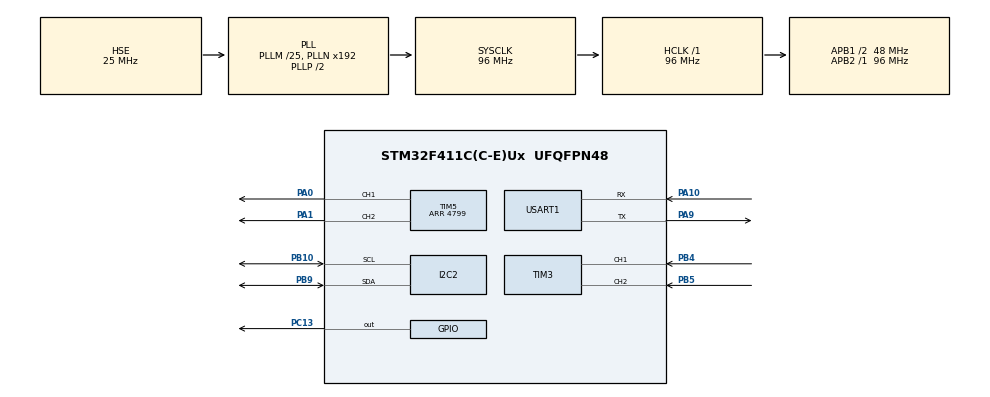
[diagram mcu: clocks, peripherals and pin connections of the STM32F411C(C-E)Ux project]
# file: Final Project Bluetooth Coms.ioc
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I2C2.I2C_Mode=I2C_Fast
Mcu.Family=STM32F4
Mcu.Name=STM32F411C(C-E)Ux
Mcu.Package=UFQFPN48
NVIC.I2C2_ER_IRQn=true\:0\:0\:false\:false\:true\:true\:true\:true
NVIC.I2C2_EV_IRQn=true\:0\:0\:false\:false\:true\:true\:true\:true
NVIC.PriorityGroup=NVIC_PRIORITYGROUP_4
NVIC.TIM3_IRQn=true\:0\:0\:false\:false\:true\:true\:true\:true
NVIC.USART1_IRQn=true\:0\:0\:false\:false\:true\:true\:true\:true
PA0-WKUP.Signal=S_TIM5_CH1
PA1.Signal=S_TIM5_CH2
PA10.Mode=Asynchronous
PA10.Signal=USART1_RX
PA13.Mode=Serial_Wire
PA13.Signal=SYS_JTMS-SWDIO
PA14.Mode=Serial_Wire
PA14.Signal=SYS_JTCK-SWCLK
PA9.Mode=Asynchronous
PA9.Signal=USART1_TX
PB10.GPIO_Pu=GPIO_NOPULL
PB10.Mode=I2C
PB10.Signal=I2C2_SCL
PB4.GPIO_ModeDefaultPP=GPIO_MODE_AF_OD
PB4.GPIO_PuPd=GPIO_PULLUP
PB4.Signal=S_TIM3_CH1
PB5.GPIO_ModeDefaultPP=GPIO_MODE_AF_OD
PB5.GPIO_PuPd=GPIO_PULLUP
PB5.Signal=S_TIM3_CH2
PB9.GPIO_Pu=GPIO_NOPULL
PB9.Mode=I2C
PB9.Signal=I2C2_SDA
PC13-ANTI_TAMP.Signal=GPIO_Output
PH0\ -\ OSC_IN.Mode=HSE-External-Oscillator
PH0\ -\ OSC_IN.Signal=RCC_OSC_IN
PH1\ -\ OSC_OUT.Mode=HSE-External-Oscillator
PH1\ -\ OSC_OUT.Signal=RCC_OSC_OUT
ProjectManager.HeapSize=0x200
ProjectManager.StackSize=0x400
ProjectManager.TargetToolchain=STM32CubeIDE
RCC.48MHZClocksFreq_Value=48000000
RCC.AHBFreq_Value=96000000
RCC.APB1CLKDivider=RCC_HCLK_DIV2
RCC.APB1Freq_Value=48000000
RCC.APB1TimFreq_Value=96000000
RCC.APB2Freq_Value=96000000
RCC.APB2TimFreq_Value=96000000
RCC.CortexFreq_Value=96000000
RCC.HCLKFreq_Value=96000000
RCC.HSE_VALUE=25000000
RCC.HSI_VALUE=16000000
RCC.LSE_VALUE=32768
RCC.PLLM=25
RCC.PLLSourceVirtual=RCC_PLLSOURCE_HSE
RCC.SYSCLKFreq_VALUE=96000000
RCC.SYSCLKSource=RCC_SYSCLKSOURCE_PLLCLK
RCC.VCOOutputFreq_Value=192000000
SH.S_TIM3_CH1.0=TIM3_CH1,Encoder_Interface
SH.S_TIM3_CH2.0=TIM3_CH2,Encoder_Interface
SH.S_TIM5_CH1.0=TIM5_CH1,PWM Generation1 CH1
SH.S_TIM5_CH2.0=TIM5_CH2,PWM Generation2 CH2
TIM2.Period=4799
TIM2.Prescaler=0
TIM3.AutoReloadPreload=TIM_AUTORELOAD_PRELOAD_DISABLE
TIM5.Channel-PWM\ Generation1\ CH1=TIM_CHANNEL_1
TIM5.Channel-PWM\ Generation2\ CH2=TIM_CHANNEL_2
TIM5.OCPolarity_1=TIM_OCPOLARITY_LOW
TIM5.OCPolarity_2=TIM_OCPOLARITY_LOW
TIM5.Period=4799
USART1.VirtualMode=VM_ASYNC
VP_TIM1_VS_ClockSourceITR.Mode=TriggerSource_ITR0
VP_TIM2_VS_ClockSourceINT.Mode=Internal
board=custom

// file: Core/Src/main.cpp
/* USER CODE BEGIN Header */
/**
  ******************************************************************************
  * @file           : main.c
  * @brief          : Main program body
  ******************************************************************************
  * @attention
  *
  * Copyright (c) 2023 STMicroelectronics.
  * All rights reserved.
  *
  * This software is licensed under terms that can be found in the LICENSE file
  * in the root directory of this software component.
  * If no LICENSE file comes with this software, it is provided AS-IS.
  *
  ******************************************************************************
  */
/* USER CODE END Header */
#include "main.h"

/* USER CODE BEGIN Includes */
#include <stdio.h>
#include "coms.h"

/* USER CODE END Includes */

I2C_HandleTypeDef hi2c2;

TIM_HandleTypeDef htim1;
TIM_HandleTypeDef htim2;
TIM_HandleTypeDef htim3;
TIM_HandleTypeDef htim5;

UART_HandleTypeDef huart1;

/* USER CODE BEGIN PV */
UART_HandleTypeDef* coms::uart;
char	coms::messbuff[10];
/* USER CODE END PV */

void SystemClock_Config(void);
static void MX_GPIO_Init(void);
static void MX_TIM2_Init(void);
static void MX_USART1_UART_Init(void);
static void MX_TIM1_Init(void);
static void MX_I2C2_Init(void);
static void MX_TIM3_Init(void);
static void MX_TIM5_Init(void);

int main(void)
{

  /* MCU Configuration--------------------------------------------------------*/

  /* Reset of all peripherals, Initializes the Flash interface and the Systick. */
  HAL_Init();

  /* Configure the system clock */
  SystemClock_Config();

  /* Initialize all configured peripherals */
  MX_GPIO_Init();
  MX_TIM2_Init();
  MX_USART1_UART_Init();
  MX_TIM1_Init();
  MX_I2C2_Init();
  MX_TIM3_Init();
  MX_TIM5_Init();

  /* Infinite loop */
  while (1)
  {

  }
}

void SystemClock_Config(void)
{
  RCC_OscInitTypeDef RCC_OscInitStruct = {0};
  RCC_ClkInitTypeDef RCC_ClkInitStruct = {0};

  /** Configure the main internal regulator output voltage
  */
  __HAL_RCC_PWR_CLK_ENABLE();
  __HAL_PWR_VOLTAGESCALING_CONFIG(PWR_REGULATOR_VOLTAGE_SCALE1);

  /** Initializes the RCC Oscillators according to the specified parameters
  * in the RCC_OscInitTypeDef structure.
  */
  RCC_OscInitStruct.OscillatorType = RCC_OSCILLATORTYPE_HSE;
  RCC_OscInitStruct.HSEState = RCC_HSE_ON;
  RCC_OscInitStruct.PLL.PLLState = RCC_PLL_ON;
  RCC_OscInitStruct.PLL.PLLSource = RCC_PLLSOURCE_HSE;
  RCC_OscInitStruct.PLL.PLLM = 25;
  RCC_OscInitStruct.PLL.PLLN = 192;
  RCC_OscInitStruct.PLL.PLLP = RCC_PLLP_DIV2;
  RCC_OscInitStruct.PLL.PLLQ = 4;
  if (HAL_RCC_OscConfig(&RCC_OscInitStruct) != HAL_OK)
  {
    Error_Handler();
  }

  /** Initializes the CPU, AHB and APB buses clocks
  */
  RCC_ClkInitStruct.ClockType = RCC_CLOCKTYPE_HCLK|RCC_CLOCKTYPE_SYSCLK
                              |RCC_CLOCKTYPE_PCLK1|RCC_CLOCKTYPE_PCLK2;
  RCC_ClkInitStruct.SYSCLKSource = RCC_SYSCLKSOURCE_PLLCLK;
  RCC_ClkInitStruct.AHBCLKDivider = RCC_SYSCLK_DIV1;
  RCC_ClkInitStruct.APB1CLKDivider = RCC_HCLK_DIV2;
  RCC_ClkInitStruct.APB2CLKDivider = RCC_HCLK_DIV1;

  if (HAL_RCC_ClockConfig(&RCC_ClkInitStruct, FLASH_LATENCY_3) != HAL_OK)
  {
    Error_Handler();
  }
}

static void MX_I2C2_Init(void)
{

  hi2c2.Instance = I2C2;
  hi2c2.Init.ClockSpeed = 400000;
  hi2c2.Init.DutyCycle = I2C_DUTYCYCLE_2;
  hi2c2.Init.OwnAddress1 = 0;
  hi2c2.Init.AddressingMode = I2C_ADDRESSINGMODE_7BIT;
  hi2c2.Init.DualAddressMode = I2C_DUALADDRESS_DISABLE;
  hi2c2.Init.OwnAddress2 = 0;
  hi2c2.Init.GeneralCallMode = I2C_GENERALCALL_DISABLE;
  hi2c2.Init.NoStretchMode = I2C_NOSTRETCH_DISABLE;
  if (HAL_I2C_Init(&hi2c2) != HAL_OK)
  {
    Error_Handler();
  }

}

static void MX_TIM1_Init(void)
{

  TIM_SlaveConfigTypeDef sSlaveConfig = {0};
  TIM_MasterConfigTypeDef sMasterConfig = {0};

  htim1.Instance = TIM1;
  htim1.Init.Prescaler = 0;
  htim1.Init.CounterMode = TIM_COUNTERMODE_UP;
  htim1.Init.Period = 65535;
  htim1.Init.ClockDivision = TIM_CLOCKDIVISION_DIV1;
  htim1.Init.RepetitionCounter = 0;
  htim1.Init.AutoReloadPreload = TIM_AUTORELOAD_PRELOAD_DISABLE;
  if (HAL_TIM_Base_Init(&htim1) != HAL_OK)
  {
    Error_Handler();
  }
  sSlaveConfig.SlaveMode = TIM_SLAVEMODE_DISABLE;
  sSlaveConfig.InputTrigger = TIM_TS_ITR0;
  if (HAL_TIM_SlaveConfigSynchro(&htim1, &sSlaveConfig) != HAL_OK)
  {
    Error_Handler();
  }
  sMasterConfig.MasterOutputTrigger = TIM_TRGO_RESET;
  sMasterConfig.MasterSlaveMode = TIM_MASTERSLAVEMODE_DISABLE;
  if (HAL_TIMEx_MasterConfigSynchronization(&htim1, &sMasterConfig) != HAL_OK)
  {
    Error_Handler();
  }

}

static void MX_TIM2_Init(void)
{

  TIM_ClockConfigTypeDef sClockSourceConfig = {0};
  TIM_MasterConfigTypeDef sMasterConfig = {0};

  htim2.Instance = TIM2;
  htim2.Init.Prescaler = 0;
  htim2.Init.CounterMode = TIM_COUNTERMODE_UP;
  htim2.Init.Period = 4799;
  htim2.Init.ClockDivision = TIM_CLOCKDIVISION_DIV1;
  htim2.Init.AutoReloadPreload = TIM_AUTORELOAD_PRELOAD_DISABLE;
  if (HAL_TIM_Base_Init(&htim2) != HAL_OK)
  {
    Error_Handler();
  }
  sClockSourceConfig.ClockSource = TIM_CLOCKSOURCE_INTERNAL;
  if (HAL_TIM_ConfigClockSource(&htim2, &sClockSourceConfig) != HAL_OK)
  {
    Error_Handler();
  }
  sMasterConfig.MasterOutputTrigger = TIM_TRGO_RESET;
  sMasterConfig.MasterSlaveMode = TIM_MASTERSLAVEMODE_DISABLE;
  if (HAL_TIMEx_MasterConfigSynchronization(&htim2, &sMasterConfig) != HAL_OK)
  {
    Error_Handler();
  }

}

static void MX_TIM3_Init(void)
{

  TIM_Encoder_InitTypeDef sConfig = {0};
  TIM_MasterConfigTypeDef sMasterConfig = {0};

  htim3.Instance = TIM3;
  htim3.Init.Prescaler = 0;
  htim3.Init.CounterMode = TIM_COUNTERMODE_UP;
  htim3.Init.Period = 65535;
  htim3.Init.ClockDivision = TIM_CLOCKDIVISION_DIV1;
  htim3.Init.AutoReloadPreload = TIM_AUTORELOAD_PRELOAD_DISABLE;
  sConfig.EncoderMode = TIM_ENCODERMODE_TI1;
  sConfig.IC1Polarity = TIM_ICPOLARITY_RISING;
  sConfig.IC1Selection = TIM_ICSELECTION_DIRECTTI;
  sConfig.IC1Prescaler = TIM_ICPSC_DIV1;
  sConfig.IC1Filter = 0;
  sConfig.IC2Polarity = TIM_ICPOLARITY_RISING;
  sConfig.IC2Selection = TIM_ICSELECTION_DIRECTTI;
  sConfig.IC2Prescaler = TIM_ICPSC_DIV1;
  sConfig.IC2Filter = 0;
  if (HAL_TIM_Encoder_Init(&htim3, &sConfig) != HAL_OK)
  {
    Error_Handler();
  }
  sMasterConfig.MasterOutputTrigger = TIM_TRGO_RESET;
  sMasterConfig.MasterSlaveMode = TIM_MASTERSLAVEMODE_DISABLE;
  if (HAL_TIMEx_MasterConfigSynchronization(&htim3, &sMasterConfig) != HAL_OK)
  {
    Error_Handler();
  }

}

static void MX_TIM5_Init(void)
{

  TIM_MasterConfigTypeDef sMasterConfig = {0};
  TIM_OC_InitTypeDef sConfigOC = {0};

  htim5.Instance = TIM5;
  htim5.Init.Prescaler = 0;
  htim5.Init.CounterMode = TIM_COUNTERMODE_UP;
  htim5.Init.Period = 4799;
  htim5.Init.ClockDivision = TIM_CLOCKDIVISION_DIV1;
  htim5.Init.AutoReloadPreload = TIM_AUTORELOAD_PRELOAD_DISABLE;
  if (HAL_TIM_PWM_Init(&htim5) != HAL_OK)
  {
    Error_Handler();
  }
  sMasterConfig.MasterOutputTrigger = TIM_TRGO_RESET;
  sMasterConfig.MasterSlaveMode = TIM_MASTERSLAVEMODE_DISABLE;
  if (HAL_TIMEx_MasterConfigSynchronization(&htim5, &sMasterConfig) != HAL_OK)
  {
    Error_Handler();
  }
  sConfigOC.OCMode = TIM_OCMODE_PWM1;
  sConfigOC.Pulse = 0;
  sConfigOC.OCPolarity = TIM_OCPOLARITY_LOW;
  sConfigOC.OCFastMode = TIM_OCFAST_DISABLE;
  if (HAL_TIM_PWM_ConfigChannel(&htim5, &sConfigOC, TIM_CHANNEL_1) != HAL_OK)
  {
    Error_Handler();
  }
  if (HAL_TIM_PWM_ConfigChannel(&htim5, &sConfigOC, TIM_CHANNEL_2) != HAL_OK)
  {
    Error_Handler();
  }
  HAL_TIM_MspPostInit(&htim5);

}

static void MX_USART1_UART_Init(void)
{

  huart1.Instance = USART1;
  huart1.Init.BaudRate = 115200;
  huart1.Init.WordLength = UART_WORDLENGTH_8B;
  huart1.Init.StopBits = UART_STOPBITS_1;
  huart1.Init.Parity = UART_PARITY_NONE;
  huart1.Init.Mode = UART_MODE_TX_RX;
  huart1.Init.HwFlowCtl = UART_HWCONTROL_NONE;
  huart1.Init.OverSampling = UART_OVERSAMPLING_16;
  if (HAL_UART_Init(&huart1) != HAL_OK)
  {
    Error_Handler();
  }

}

static void MX_GPIO_Init(void)
{
  GPIO_InitTypeDef GPIO_InitStruct = {0};

  /* GPIO Ports Clock Enable */
  __HAL_RCC_GPIOC_CLK_ENABLE();
  __HAL_RCC_GPIOH_CLK_ENABLE();
  __HAL_RCC_GPIOA_CLK_ENABLE();
  __HAL_RCC_GPIOB_CLK_ENABLE();

  /*Configure GPIO pin Output Level */
  HAL_GPIO_WritePin(GPIOC, GPIO_PIN_13, GPIO_PIN_RESET);

  /*Configure GPIO pin : PC13 */
  GPIO_InitStruct.Pin = GPIO_PIN_13;
  GPIO_InitStruct.Mode = GPIO_MODE_OUTPUT_PP;
  GPIO_InitStruct.Pull = GPIO_NOPULL;
  GPIO_InitStruct.Speed = GPIO_SPEED_FREQ_LOW;
  HAL_GPIO_Init(GPIOC, &GPIO_InitStruct);

}

void Error_Handler(void)
{
  __disable_irq();
  while (1)
  {
  }
}
